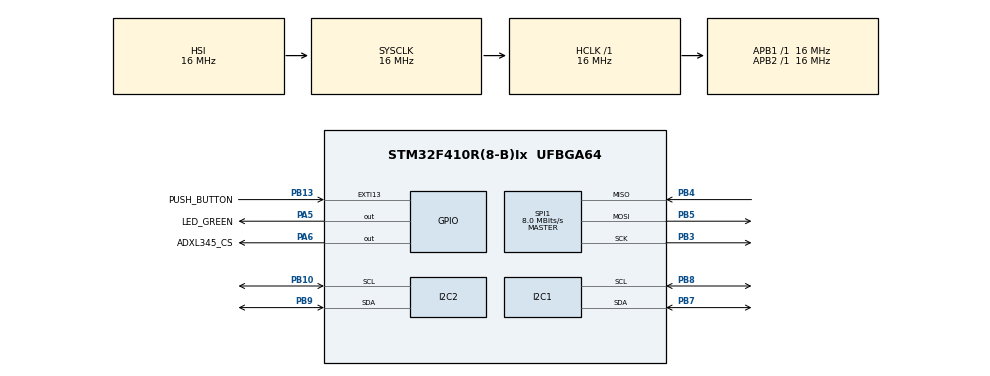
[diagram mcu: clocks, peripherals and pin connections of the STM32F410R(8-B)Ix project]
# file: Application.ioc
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FREERTOS.Tasks01=Sensing,0,128,Sensing_Task,Default,NULL,Dynamic,NULL,NULL;Processing,0,128,Processing_Task,Default,NULL,Dynamic,NULL,NULL;Sending,-3,128,Sending_Task,Default,NULL,Dynamic,NULL,NULL
Mcu.Family=STM32F4
Mcu.Name=STM32F410R(8-B)Ix
Mcu.Package=UFBGA64
NVIC.PriorityGroup=NVIC_PRIORITYGROUP_4
NVIC.TIM6_DAC_IRQn=true\:0\:0\:false\:false\:true\:false\:false\:true
NVIC.TimeBase=TIM6_DAC_IRQn
NVIC.TimeBaseIP=TIM6
PA13.Mode=Serial_Wire
PA13.Signal=SYS_JTMS-SWDIO
PA14.Mode=Serial_Wire
PA14.Signal=SYS_JTCK-SWCLK
PA5.GPIO_Label=LED_GREEN
PA5.Signal=GPIO_Output
PA6.GPIO_Label=ADXL345_CS
PA6.Signal=GPIO_Output
PB10.Mode=I2C
PB10.Signal=I2C2_SCL
PB13.GPIO_Label=PUSH_BUTTON
PB13.Signal=GPXTI13
PB3.Mode=Full_Duplex_Master
PB3.Signal=SPI1_SCK
PB4.Mode=Full_Duplex_Master
PB4.Signal=SPI1_MISO
PB5.Mode=Full_Duplex_Master
PB5.Signal=SPI1_MOSI
PB7.Mode=I2C
PB7.Signal=I2C1_SDA
PB8.Mode=I2C
PB8.Signal=I2C1_SCL
PB9.Mode=I2C
PB9.Signal=I2C2_SDA
PC14-OSC32_IN.Mode=LSE-External-Oscillator
PC14-OSC32_IN.Signal=RCC_OSC32_IN
PC15-OSC32_OUT.Mode=LSE-External-Oscillator
PC15-OSC32_OUT.Signal=RCC_OSC32_OUT
PH0\ -\ OSC_IN.Mode=HSE-External-Oscillator
PH0\ -\ OSC_IN.Signal=RCC_OSC_IN
PH1\ -\ OSC_OUT.Mode=HSE-External-Oscillator
PH1\ -\ OSC_OUT.Signal=RCC_OSC_OUT
ProjectManager.HeapSize=0x200
ProjectManager.StackSize=0x400
ProjectManager.TargetToolchain=STM32CubeIDE
RCC.AHBFreq_Value=16000000
RCC.APB1Freq_Value=16000000
RCC.APB2Freq_Value=16000000
RCC.CortexFreq_Value=16000000
RCC.HSE_VALUE=25000000
RCC.HSI_VALUE=16000000
RCC.SYSCLKFreq_VALUE=16000000
RCC.VCOOutputFreq_Value=192000000
SPI1.CalculateBaudRate=8.0 MBits/s
SPI1.Direction=SPI_DIRECTION_2LINES
SPI1.Mode=SPI_MODE_MASTER
SPI1.VirtualType=VM_MASTER
VP_FREERTOS_VS_CMSIS_V1.Mode=CMSIS_V1
VP_SYS_VS_tim6.Mode=TIM6
board=custom

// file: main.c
/* USER CODE BEGIN Header */
/**
  ******************************************************************************
  * @file           : main.c
  * @brief          : Main program body
  ******************************************************************************
  * @attention
  *
  * <h2><center>&copy; Copyright (c) 2021 STMicroelectronics.
  * All rights reserved.</center></h2>
  *
  * This software component is licensed by ST under BSD 3-Clause license,
  * the "License"; You may not use this file except in compliance with the
  * License. You may obtain a copy of the License at:
  *                        opensource.org/licenses/BSD-3-Clause
  *
  ******************************************************************************
  */
/* USER CODE END Header */

#include "main.h"
#include "cmsis_os.h"
#include "ADXL345.h"

/* USER CODE BEGIN Includes */
extern uint8_t chave;

/* USER CODE END Includes */

I2C_HandleTypeDef hi2c1;
I2C_HandleTypeDef hi2c2;

SPI_HandleTypeDef hspi1;

osThreadId SensingHandle;
osThreadId ProcessingHandle;
osThreadId SendingHandle;

void SystemClock_Config(void);
static void MX_GPIO_Init(void);
static void MX_I2C1_Init(void);
static void MX_I2C2_Init(void);
static void MX_SPI1_Init(void);
void Sensing_Task(void const * argument);
void Processing_Task(void const * argument);
void Sending_Task(void const * argument);

int main(void)
{

  /* MCU Configuration--------------------------------------------------------*/

  /* Reset of all peripherals, Initializes the Flash interface and the Systick. */
  HAL_Init();

  /* Configure the system clock */
  SystemClock_Config();

  /* Initialize all configured peripherals */
  MX_GPIO_Init();
  MX_I2C1_Init();
  MX_I2C2_Init();
  MX_SPI1_Init();

  /* Create the thread(s) */
  /* definition and creation of Sensing */
  osThreadDef(Sensing, Sensing_Task, osPriorityNormal, 0, 128);
  SensingHandle = osThreadCreate(osThread(Sensing), NULL);

  /* definition and creation of Processing */
  osThreadDef(Processing, Processing_Task, osPriorityNormal, 0, 128);
  ProcessingHandle = osThreadCreate(osThread(Processing), NULL);

  /* definition and creation of Sending */
  osThreadDef(Sending, Sending_Task, osPriorityIdle, 0, 128);
  SendingHandle = osThreadCreate(osThread(Sending), NULL);

  /* Start scheduler */
  osKernelStart();

  /* We should never get here as control is now taken by the scheduler */
  /* Infinite loop */
  while (1)
  {

  }
}

void SystemClock_Config(void)
{
  RCC_OscInitTypeDef RCC_OscInitStruct = {0};
  RCC_ClkInitTypeDef RCC_ClkInitStruct = {0};

  /** Configure the main internal regulator output voltage
  */
  __HAL_RCC_PWR_CLK_ENABLE();
  __HAL_PWR_VOLTAGESCALING_CONFIG(PWR_REGULATOR_VOLTAGE_SCALE1);
  /** Initializes the CPU, AHB and APB busses clocks
  */
  RCC_OscInitStruct.OscillatorType = RCC_OSCILLATORTYPE_HSI;
  RCC_OscInitStruct.HSIState = RCC_HSI_ON;
  RCC_OscInitStruct.HSICalibrationValue = RCC_HSICALIBRATION_DEFAULT;
  RCC_OscInitStruct.PLL.PLLState = RCC_PLL_NONE;
  if (HAL_RCC_OscConfig(&RCC_OscInitStruct) != HAL_OK)
  {
    Error_Handler();
  }
  /** Initializes the CPU, AHB and APB busses clocks
  */
  RCC_ClkInitStruct.ClockType = RCC_CLOCKTYPE_HCLK|RCC_CLOCKTYPE_SYSCLK
                              |RCC_CLOCKTYPE_PCLK1|RCC_CLOCKTYPE_PCLK2;
  RCC_ClkInitStruct.SYSCLKSource = RCC_SYSCLKSOURCE_HSI;
  RCC_ClkInitStruct.AHBCLKDivider = RCC_SYSCLK_DIV1;
  RCC_ClkInitStruct.APB1CLKDivider = RCC_HCLK_DIV1;
  RCC_ClkInitStruct.APB2CLKDivider = RCC_HCLK_DIV1;

  if (HAL_RCC_ClockConfig(&RCC_ClkInitStruct, FLASH_LATENCY_0) != HAL_OK)
  {
    Error_Handler();
  }
}

static void MX_I2C1_Init(void)
{

  hi2c1.Instance = I2C1;
  hi2c1.Init.ClockSpeed = 100000;
  hi2c1.Init.DutyCycle = I2C_DUTYCYCLE_2;
  hi2c1.Init.OwnAddress1 = 0;
  hi2c1.Init.AddressingMode = I2C_ADDRESSINGMODE_7BIT;
  hi2c1.Init.DualAddressMode = I2C_DUALADDRESS_DISABLE;
  hi2c1.Init.OwnAddress2 = 0;
  hi2c1.Init.GeneralCallMode = I2C_GENERALCALL_DISABLE;
  hi2c1.Init.NoStretchMode = I2C_NOSTRETCH_DISABLE;
  if (HAL_I2C_Init(&hi2c1) != HAL_OK)
  {
    Error_Handler();
  }

}

static void MX_I2C2_Init(void)
{

  hi2c2.Instance = I2C2;
  hi2c2.Init.ClockSpeed = 100000;
  hi2c2.Init.DutyCycle = I2C_DUTYCYCLE_2;
  hi2c2.Init.OwnAddress1 = 0;
  hi2c2.Init.AddressingMode = I2C_ADDRESSINGMODE_7BIT;
  hi2c2.Init.DualAddressMode = I2C_DUALADDRESS_DISABLE;
  hi2c2.Init.OwnAddress2 = 0;
  hi2c2.Init.GeneralCallMode = I2C_GENERALCALL_DISABLE;
  hi2c2.Init.NoStretchMode = I2C_NOSTRETCH_DISABLE;
  if (HAL_I2C_Init(&hi2c2) != HAL_OK)
  {
    Error_Handler();
  }

}

static void MX_SPI1_Init(void)
{

  /* SPI1 parameter configuration*/
  hspi1.Instance = SPI1;
  hspi1.Init.Mode = SPI_MODE_MASTER;
  hspi1.Init.Direction = SPI_DIRECTION_2LINES;
  hspi1.Init.DataSize = SPI_DATASIZE_8BIT;
  hspi1.Init.CLKPolarity = SPI_POLARITY_LOW;
  hspi1.Init.CLKPhase = SPI_PHASE_1EDGE;
  hspi1.Init.NSS = SPI_NSS_SOFT;
  hspi1.Init.BaudRatePrescaler = SPI_BAUDRATEPRESCALER_2;
  hspi1.Init.FirstBit = SPI_FIRSTBIT_MSB;
  hspi1.Init.TIMode = SPI_TIMODE_DISABLE;
  hspi1.Init.CRCCalculation = SPI_CRCCALCULATION_DISABLE;
  hspi1.Init.CRCPolynomial = 15;
  if (HAL_SPI_Init(&hspi1) != HAL_OK)
  {
    Error_Handler();
  }

}

static void MX_GPIO_Init(void)
{
  GPIO_InitTypeDef GPIO_InitStruct = {0};

  /* GPIO Ports Clock Enable */
  __HAL_RCC_GPIOC_CLK_ENABLE();
  __HAL_RCC_GPIOB_CLK_ENABLE();
  __HAL_RCC_GPIOA_CLK_ENABLE();
  __HAL_RCC_GPIOH_CLK_ENABLE();

  /*Configure GPIO pin Output Level */
  HAL_GPIO_WritePin(GPIOA, LED_GREEN_Pin|ADXL345_CS_Pin, GPIO_PIN_RESET);

  /*Configure GPIO pins : LED_GREEN_Pin ADXL345_CS_Pin */
  GPIO_InitStruct.Pin = LED_GREEN_Pin|ADXL345_CS_Pin;
  GPIO_InitStruct.Mode = GPIO_MODE_OUTPUT_PP;
  GPIO_InitStruct.Pull = GPIO_NOPULL;
  GPIO_InitStruct.Speed = GPIO_SPEED_FREQ_LOW;
  HAL_GPIO_Init(GPIOA, &GPIO_InitStruct);

  /*Configure GPIO pin : PUSH_BUTTON_Pin */
  GPIO_InitStruct.Pin = PUSH_BUTTON_Pin;
  GPIO_InitStruct.Mode = GPIO_MODE_IT_RISING;
  GPIO_InitStruct.Pull = GPIO_NOPULL;
  HAL_GPIO_Init(PUSH_BUTTON_GPIO_Port, &GPIO_InitStruct);

}

void Sensing_Task(void const * argument)
{
	/* USER CODE BEGIN 5 */

	/* Infinite loop */
	for(;;)
	{
		ADXL345_DevIDRead(&hi2c1);
		ADXL345_DataRead(&hi2c1);
		osDelay(300);
	}
	/* USER CODE END 5 */
}

void Processing_Task(void const * argument)
{
  /* USER CODE BEGIN Processing_Task */
  /* Infinite loop */
  for(;;)
  {

	osDelay(300);
  }
  /* USER CODE END Processing_Task */
}

void Sending_Task(void const * argument)
{
  /* USER CODE BEGIN Sending_Task */
  /* Infinite loop */
  for(;;)
  {

    //osDelay(100);
  }
  /* USER CODE END Sending_Task */
}

 /**
  * @brief  Period elapsed callback in non blocking mode
  * @note   This function is called  when TIM6 interrupt took place, inside
  * HAL_TIM_IRQHandler(). It makes a direct call to HAL_IncTick() to increment
  * a global variable "uwTick" used as application time base.
  * @param  htim : TIM handle
  * @retval None
  */
void HAL_TIM_PeriodElapsedCallback(TIM_HandleTypeDef *htim)
{
  if (htim->Instance == TIM6) {
    HAL_IncTick();
  }
}

void Error_Handler(void)
{
}

/************************ (C) COPYRIGHT STMicroelectronics *****END OF FILE****/
